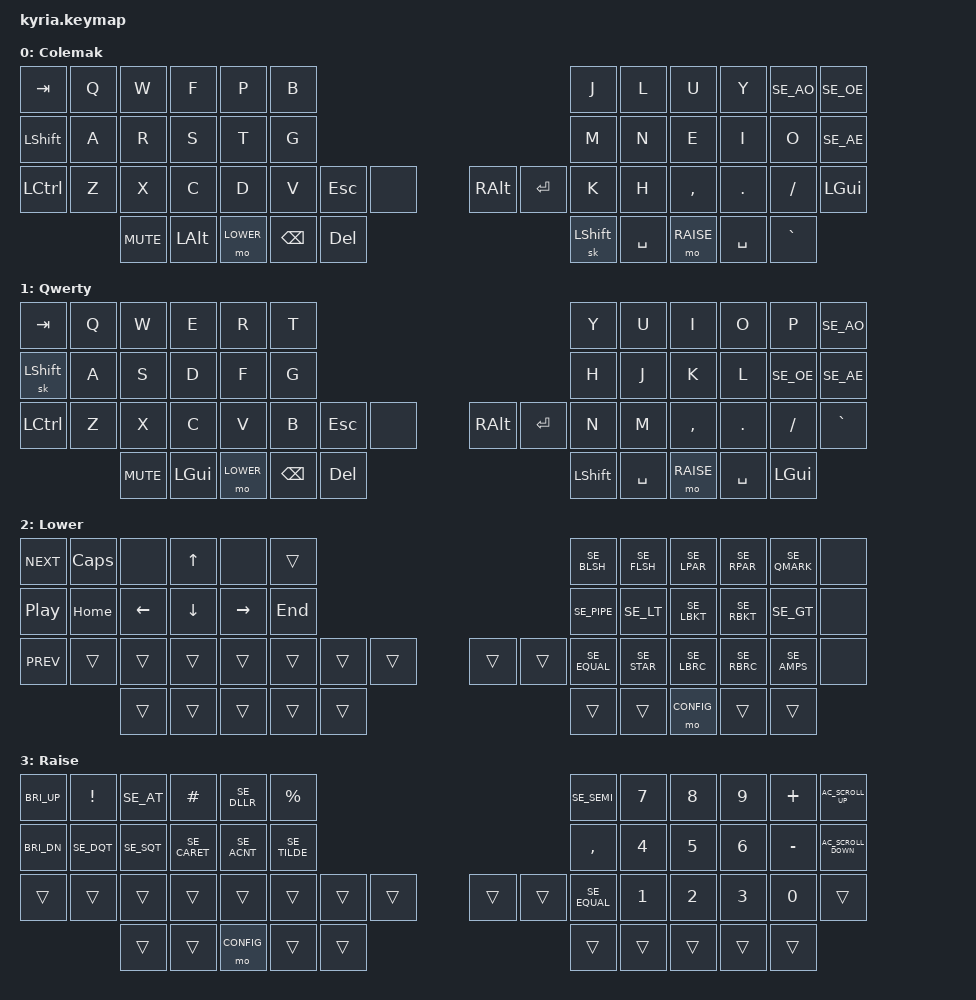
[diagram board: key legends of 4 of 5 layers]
/*
 * Copyright (c) 2020 The ZMK Contributors
 *
 * SPDX-License-Identifier: MIT
 */

#include <behaviors.dtsi>
#include <dt-bindings/zmk/keys.h>
#include "swedish_keys.h"

#define COLEMAK 0
#define QWERTY  1
#define LOWER   2
#define RAISE   3
#define CONFIG  4 

&left_encoder { resolution = <1>; };
&right_encoder { resolution = <1>; };


&sk { // release sticky key directly after next press
    quick-release;
};

/ {
	keymap {
		compatible = "zmk,keymap";

			Colemak {
// ---------------------------------------------------------------------------------------------------------------------------------
// |  TAB |  Q  |  W  |  F  |  P   |  B   |                                  |  J   |  L  |  U  |  Y  |  Å  |   Ö  |
// | SHIFT|  A  |  R  |  S  |  T   |  G   |                                  |  M   |  N  |  E  |  I  |  O  |   Ä  |
// | CRTL |  Z  |  X  |  C  |  D   |  V   | ESC  |     |     |       |  RET  |  K   |  H  |  ,  |  .  |  -  |L GUI |
//                    |MUTE |L ALT |LOWER | BSPC | DEL |     | SHIFT | SPACE |RAISE |     |TERM |

			bindings = <
	&kp TAB   &kp Q &kp W &kp F &kp P &kp B                                                &kp J &kp L  &kp U  &kp Y   &kp SE_AO &kp SE_OE
	&kp LSHFT &kp A &kp R &kp S &kp T &kp G                                                &kp M &kp N  &kp E  &kp I   &kp O &kp SE_AE
	&kp LCTRL &kp Z &kp X &kp C &kp D &kp V &kp ESC &none             &kp RALT &kp RET  &kp K &kp H  &kp COMMA &kp DOT &kp FSLH &kp LGUI
	                 &kp C_MUTE &kp LALT &mo LOWER &kp BSPC &kp DEL        &sk LSHFT  &kp SPACE &mo RAISE &kp SPACE &kp GRAVE
			>;

			sensor-bindings = <&inc_dec_kp C_VOL_DN C_VOL_UP &inc_dec_kp PG_DN PG_UP>;
		};
		
			Qwerty{
// ---------------------------------------------------------------------------------------------------------------------------------
// |  TAB  |  Q  |  W  |  E   |  R   |  T   |                                          |  Y   |  U    |  I    |  O   |   P   |   Å  |
// | SHIFT |  A  |  S  |  D   |  F   |  G   |                                          |  H   |  J    |  K    |  L   |   Ö   |   Ä  |
// | CTRL  |  Z  |  X  |  C   |  V   |  B   | ESC  |     |            |       |  RET   |  N   |  M    |  ,    |  .   |   -   | TERM |
//                     | MUTE  | DEL  |LOWER | BSPC | DEL |            | SHIFT | SPACE |RAISE |    | L GUI |

			bindings = <
	&kp TAB   &kp Q &kp W  &kp E  &kp R   &kp T                                                 &kp Y &kp U  &kp I     &kp O   &kp P     &kp SE_AO
	&sk LSHFT &kp A &kp S  &kp D  &kp F   &kp G                                                 &kp H &kp J  &kp K     &kp L   &kp SE_OE &kp SE_AE
	&kp LCTRL &kp Z &kp X  &kp C  &kp V   &kp B  &kp ESC  &none                &kp RALT &kp RET &kp N &kp M  &kp COMMA &kp DOT &kp FSLH  &kp GRAVE
	                       &kp C_MUTE &kp LGUI &mo LOWER &kp BSPC &kp DEL        &kp LSHFT  &kp SPACE  &mo RAISE &kp SPACE &kp LGUI
			>;

			sensor-bindings = <&inc_dec_kp C_VOL_UP C_VOL_DN &inc_dec_kp PG_UP PG_DN>;
		};
		Lower {
// ---------------------------------------------------------------------------------------------------------------------------------
// |next |CAPS |     |  UP  |      |     |                           |  \  |  /  | (  |  )  | ?  |vol up|
// |play |HOME |LEFT | DOWN |RIGHT | END |                           |  |  |  <  | [  |  ]  | >  |vol down|
// |prev |     |     |      |      |     |    |    |         |   |   |  =  |  *  | {  |  }  | &  |mute|
//                          |      |     |    |    |         |   |   |CONFIG|     |    |

			bindings = <
	&kp C_NEXT  &kp CAPS &none &kp UP   &none &trans                                   &kp SE_BLSH  &kp SE_FLSH &kp SE_LPAR &kp SE_RPAR &kp SE_QMARK &none
	&kp C_PP    &kp HOME &kp LEFT  &kp DOWN &kp RIGHT &kp END                                  &kp SE_PIPE  &kp SE_LT   &kp SE_LBKT &kp SE_RBKT &kp SE_GT    &none
	&kp C_PREV  &trans   &trans    &trans   &trans    &trans &trans &trans     &trans  &trans  &kp SE_EQUAL &kp SE_STAR &kp SE_LBRC &kp SE_RBRC &kp SE_AMPS  &none
	                                &trans   &trans    &trans &trans &trans     &trans  &trans  &mo CONFIG   &trans     &trans
			>;

		};
  		
		Raise {
// ---------------------------------------------------------------------------------------------------------------------------------
// |brightness up  |  !  |  @  |  #  |  $  |  %   |                            |  :  |  7  |  8  |  9  | +  |scroll up|
// |brightness down|  "  |  '  |  ^  |  ´  |  ~   |                            |  ;  |  4  |  5  |  6  | -  |scroll down|
// |               |     |     |     |     |      |    |    |        |    |    |  =  |  1  |  2  |  3  | 0  |   |
//                             |     |     |CONFIG|    |    |        |    |    |     |     |     |

			bindings = <
   &kp C_BRI_UP  &kp EXCL  &kp SE_AT &kp HASH &kp SE_DLLR &kp PRCNT                      &kp SE_SEMI  &kp N7  &kp N8  &kp N9  &kp PLUS  &kp C_AC_SCROLL_UP
   &kp C_BRI_DN  &kp SE_DQT &kp SE_SQT  &kp SE_CARET &kp SE_ACNT &kp SE_TILDE             &kp COMMA &kp N4  &kp N5  &kp N6  &kp MINUS &kp C_AC_SCROLL_DOWN
   &trans  &trans  &trans  &trans &trans &trans &trans &trans         &trans &trans &kp SE_EQUAL &kp N1  &kp N2  &kp N3  &kp N0    &trans	
	                                  &trans &trans &mo CONFIG &trans       &trans &trans &trans &trans &trans &trans
			>;

		};

		Config {
// ---------------------------------------------------------------------------------------------------------------------------------
// |COLEMAK| F1 | F2 | F3 | F4 | F5 |                           | F6 | F7 | F8 |F9 |F10 |   |
// |QWERTY |    |    |    |    |F11 |                           | F12|    |    |    |   |   |
// |       |    |    |    |    |    |    |    |        |   |    |    |    |    |    |   |   |
//                     |    |    |    |    |              |   |    |    |    |    |

			bindings = <
   &to COLEMAK  &kp F1  &kp F2 &kp F3 &kp F4 &kp F5 				       &kp F6 &kp F7  &kp F8  &kp F9  &kp F10 &trans
   &to QWERTY  &trans  &trans  &trans  &trans  &kp F11                                 &kp F12  &trans  &trans  &trans  &trans  &trans
   &trans  &trans  &trans  &trans  &trans  &trans  &trans  &trans     &trans  &trans  &trans  &trans  &trans  &trans  &trans  &trans
			           &trans  &trans  &trans  &trans     &trans  &trans  &trans  &trans
			>;

		};
	};
};
